# AC7802x register map
Vendor: AutoChips; Series: AC78; File version: 1.0
CPU: CM0PLUS r0p1, little endian, no MPU, no FPU, VTOR, 2 interrupt priority bits
Registers are 32-bit, read-write, reset 0x0 unless marked. A register's access mark holds for its fields unless they carry their own. Offsets are from the block's base; [hi:lo] are bit positions; {n}, {i} and the like mark numbered series; 'fields as' and 'values as' point back to an identical list.

## PWM2 — Pulse Width Modulation
Base 0x40015000
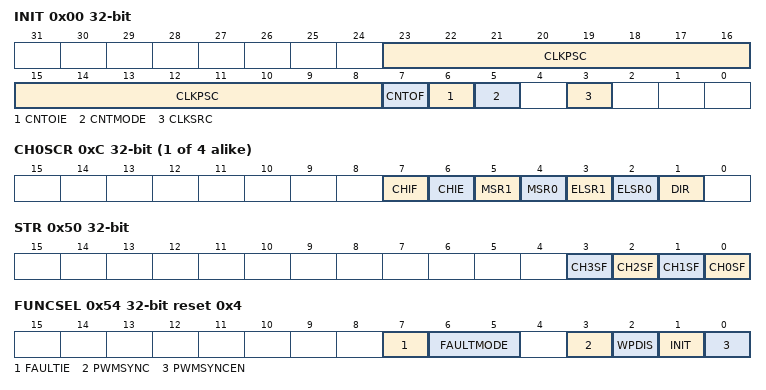
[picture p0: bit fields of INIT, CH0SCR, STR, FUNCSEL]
0x00 INIT — PWM Initialize, Include Clock and Prescale Setting
  [23:8] CLKPSC — Prescale Factor Selection
  [7] CNTOF — PWM Counter Overflow Flag
    0=PWM counter has not overflowed; 1=PWM counter has overflowed
  [6] CNTOIE — PWM Counter Overflow Interrupt Enable
    0=Disable CNTOF interrupts. Use software polling.; 1=Enable CNTOF interrupts. An interrupt is generated when CNTOF equals one.
  [5] CNTMODE — PWM Counter Mode Select
    0=Up Counting mode; 1=Up-Down Counting mode
  [3] CLKSRC — Clock Source Selection
    0=No clock selected. This in effect disables the PWM counter.; 1=APB clock
0x04 CNT — PWM Counter Current Count Value
  [15:0] COUNT — Current Counter Value
0x08 MCVR — PWM Counter Max Count Value Register
  [15:0] MCVR — Counter Max Count Value
{0xC+8i} CH{i}SCR (i=0..3) — Channel (n) Status And Control Register
  [7] CHIF — Channel Interrupt Flag
    0=No channel event has occurred; 1=Channel event has occurred
  [6] CHIE — Channel Interrupt Enable
    0=Disable channel interrupts. Use software polling.; 1=Enable channel interrupts
  [5] MSR1 — Channel Mode Select Register 1
  [4] MSR0 — Channel Mode Select Register 0
  [3] ELSR1 — Edge or Level Select Register 1
  [2] ELSR0 — Edge or Level Select Register 0
  [1] DIR — Match point direction
    0=Down count match; 1=Up count match
{0x10+8i} CH{i}V (i=0..3) — Channel (n) Value
  [15:0] CHCVAL — Channel Count Value
0x4C CNTIN — Counter Initial Value
  [15:0] CNTINIT
0x50 STR — Status Register
  [all] fields
    values as CH0SCR.CHIF
  [n] CH{n}SF (n=0..3) — Channel {n} Status Flag
0x54 FUNCSEL reset 0x4 — PWM Features(Functions) Mode Selection Register
  [7] FAULTIE — Fault Interrupt Enable
    0=Fault control interrupt is disabled; 1=Fault control interrupt is enabled
  [6:5] FAULTMODE — Fault Control Mode
    0=Fault control is disabled for all channels; 1=Fault control is enabled for even channels only (channels 0, 2, 4, and 6), and the selected mode is the manual fault clearing; 2=Fault control is enabled for all channels, and the selected mode is the manual fault clearing; 3=Fault control is enabled for all channels, and the selected mode is the automatic fault clearing
  [3] PWMSYNC — PWM Synchronization Mode
    0=No restrictions. Software and hardware triggers can be used by MOD, CnV, OUTMASK, and PWM counter synchronization.; 1=Software trigger can only be used by MOD and CnV synchronization, and hardware triggers can only be used by OUTMASK and PWM counter synchronization
  [2] WPDIS — Write Protection Enable Register
    0=Write protection is enabled; 1=Write protection is disabled
  [1] INIT — Initialize The Channels Output
  [0] PWMSYNCEN — PWM Synchronization functio Enable
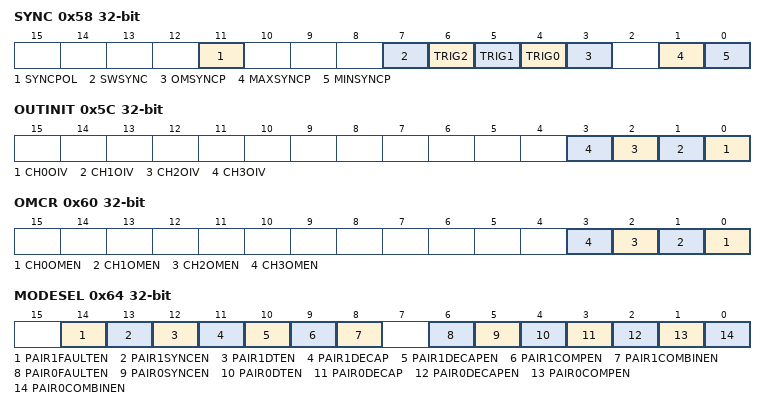
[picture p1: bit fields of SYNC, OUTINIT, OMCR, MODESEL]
0x58 SYNC — Synchronization
  [11] SYNCPOL — CHPOLR Register Synchronization
    0=CHPOLR register is updated with its buffer value at all rising edges of system clock; 1=CHPOLR register is updated with its buffer value by the PWM synchronization
  [7] SWSYNC — PWM Synchronization Software Trigger
    0=Software trigger is not selected; 1=Software trigger is selected
  [6] TRIG2 — PWM Synchronization Hardware Trigger 2
    0=Trigger is disabled; 1=Trigger is enabled
  [5] TRIG1 — PWM Synchronization Hardware Trigger 1
    0=Trigger is disabled; 1=Trigger is enabled
  [4] TRIG0 — PWM Synchronization Hardware Trigger 0
    0=Trigger is disabled; 1=Trigger is enabled
  [3] OMSYNCP — Output Mask Synchronization Point
    0=OUTMASK register is updated with the value of its buffer in all rising edges of the system clock; 1=OUTMASK register is updated with the value of its buffer only by the PWM synchronization
  [1] MAXSYNCP — Maximum Loading Point Enable
    0=The maximum loading point is disabled; 1=The maximum loading point is enabled
  [0] MINSYNCP — Minimum Loading Point Enable
    0=The minimum loading point is disabled; 1=The minimum loading point is enabled
0x5C OUTINIT — Initial Value For Channels Output
  [all] fields
    0=The initialization value is 0; 1=The initialization value is 1
  [n] CH{n}OIV (n=0..3) — Channel {n} Output Initialization Value
0x60 OMCR — Output Mask Control Register
  [all] fields
    0=Channel output is not masked. It continues to operate normally.; 1=Channel output is masked. It is forced to its inactive state.
  [n] CH{n}OMEN (n=0..3) — Channel {n} Output Mask
0x64 MODESEL — PWM Function Mode Selection
  [14] PAIR1FAULTEN — Fault Control Enable For Pair1
    0=The fault control in this pair of channels is disabled; 1=The fault control in this pair of channels is enabled
  [13] PAIR1SYNCEN — Synchronization Enable For Pair1
    0=The PWM synchronization in this pair of channels is disabled; 1=The PWM synchronization in this pair of channels is enabled
  [12] PAIR1DTEN — Deadtime Enable For Pair1
    0=The deadtime insertion in this pair of channels is disabled; 1=The deadtime insertion in this pair of channels is enabled
  [11] PAIR1DECAP — Dual Edge Capture Mode Captures For Pair1
    0=The dual edge captures are inactive; 1=The dual edge captures are active
  [10] PAIR1DECAPEN — Dual Edge Capture Mode Enable For Pair1
    0=The Dual Edge Capture mode in this pair of channels is disabled; 1=The Dual Edge Capture mode in this pair of channels is enabled
  [9] PAIR1COMPEN — Complement Of Channel (n) For Pair1
    0=The channel 3 output is the same as the channel 2 output; 1=The channel 3 output is the complement of the channel 2 output
  [8] PAIR1COMBINEN — Combine Channels For Pair1
    0=Channels 2 and 3 are independent; 1=Channels 2 and 3 are combined
  [6] PAIR0FAULTEN — Fault Control Enable for Pair0
    values as PAIR1FAULTEN
  [5] PAIR0SYNCEN — Synchronization Enable for Pair0
    values as PAIR1SYNCEN
  [4] PAIR0DTEN — Deadtime Enable for Pair0
    values as PAIR1DTEN
  [3] PAIR0DECAP — Dual Edge Capture Mode Captures for Pair0
    values as PAIR1DECAP
  [2] PAIR0DECAPEN — Dual Edge Capture Mode Enable for Pair0
    values as PAIR1DECAPEN
  [1] PAIR0COMPEN — Complement Channels for Pair0
    0=The channel 1 output is the same as the channel 0 output; 1=The channel 1 output is the complement of the channel 0 output
  [0] PAIR0COMBINEN — Combine Channels For Pair0
    0=Channels 0 and 1 are independent; 1=Channels 0 and 1 are combined
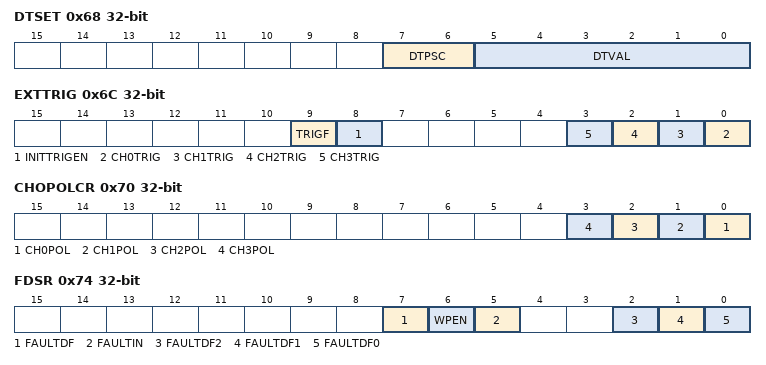
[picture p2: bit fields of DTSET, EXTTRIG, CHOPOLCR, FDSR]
0x68 DTSET — Deadtime Setting Register
  [7:6] DTPSC — Deadtime Prescaler Control Value
    0b0x=Divide the system clock by 1; 2=Divide the system clock by 4; 3=Divide the system clock by 16
  [5:0] DTVAL — Deadtime Value
0x6C EXTTRIG — PWM External Trigger
  [9] TRIGF — Channel Trigger Flag
    0=No channel trigger was generated; 1=A channel trigger was generated
  [8] INITTRIGEN — Initialization Trigger Enable
    0=The generation of initialization trigger is disabled; 1=The generation of initialization trigger is enabled
  [n] CH{n}TRIG (n=0..3) — Channel {n} Trigger Enable
    0=The generation of the channel trigger is disabled; 1=The generation of the channel trigger is enabled
0x70 CHOPOLCR — Channel Output Polarity Register
  [all] fields
    0=The channel polarity is active high; 1=The channel polarity is active low
  [n] CH{n}POL (n=0..3) — Channel {n} Polarity
0x74 FDSR — Fault Detect Status Register
  [7] FAULTDF ro — Fault Detection Flag
    0=No fault condition was detected; 1=A fault condition was detected
  [6] WPEN — Write Protection Enable
    0=Write protection is disabled. Write protected bits can be written.; 1=Write protection is enabled. Write protected bits cannot be written.
  [5] FAULTIN ro — Fault Inputs
    0=The logic OR of the enabled fault inputs is 0; 1=The logic OR of the enabled fault inputs is 1
  [2] FAULTDF2 ro — Fault Detection Flag 2
    0=No fault condition was detected at the fault input; 1=A fault condition was detected at the fault input
  [1] FAULTDF1 ro — Fault Detection Flag 1
    values as FAULTDF2
  [0] FAULTDF0 ro — Fault Detection Flag 0
    values as FAULTDF2
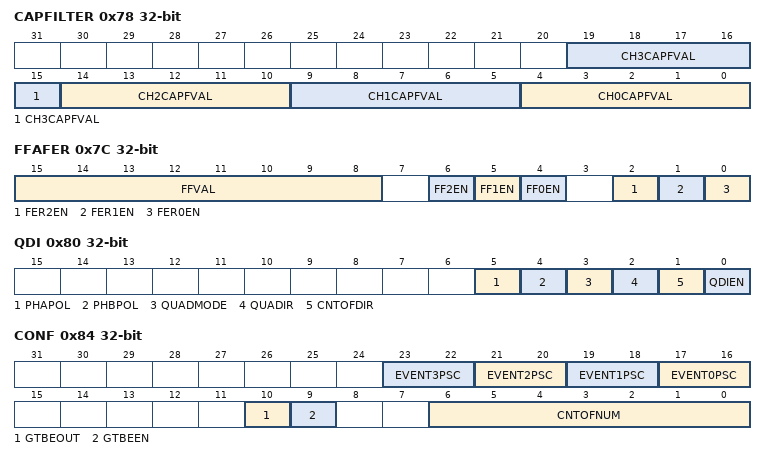
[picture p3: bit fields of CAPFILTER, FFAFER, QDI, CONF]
0x78 CAPFILTER — Input Capture Filter Control
  [5n+4:5n] CH{n}CAPFVAL (n=0..3) — Channel {n} Input Filter
0x7C FFAFER — Fault Filter and Fault Enable Register
  [15:8] FFVAL — Fault Input Filter
  [6] FF2EN — Fault Input 2 Filter Enable
    0=Fault input filter is disabled; 1=Fault input filter is enabled
  [5] FF1EN — Fault Input 1 Filter Enable
    values as FF2EN
  [4] FF0EN — Fault Input 0 Filter Enable
    values as FF2EN
  [2] FER2EN — Fault Input 2 Enable
    0=Fault input is disabled; 1=Fault input is enabled
  [1] FER1EN — Fault Input 1 Enable
    0=Fault input is disabled; 1=Fault input is enabled
  [0] FER0EN — Fault Input 0 Enable
    0=Fault input is disabled; 1=Fault input is enabled
0x80 QDI — Quadrature Decoder Interface Configuration Register
  [5] PHAPOL — Phase A Input Polarity
    0=Normal polarity; 1=Inverted polarity
  [4] PHBPOL — Phase B Input Polarity
    0=Normal polarity; 1=Inverted polarity
  [3] QUADMODE — Quadrature Decoder Mode
    0=Phase A and phase B encoding mode; 1=Count and direction encoding mode
  [2] QUADIR ro — Counting Direction
    0=Counting direction is decreasing; 1=Counting direction is increasing
  [1] CNTOFDIR ro — Overflow Direction
    0=Set on the bottom of counting; 1=Set on the top of counting
  [0] QDIEN — Quadrature Decoder Mode Enable
    0=Quadrature Decoder is Disable; 1=Quadrature Decoder is Enable
0x84 CONF — Configuration
  [2n+17:2n+16] EVENT{n}PSC (n=0..3) — Channel{n} input event prescaler
    0=Event divided by 1; 1=Event divided by 2; 2=Event divided by 4; 3=Event divided by 8
  [10] GTBEOUT — Global Time Base Output
    0=Global time base signal generation is disabled; 1=Global time base signal generation is enabled
  [9] GTBEEN — Global Time Base Enable
    0=Global time base is disabled; 1=Global time base is enabled
  [6:0] CNTOFNUM — Count Overflow Flag Number
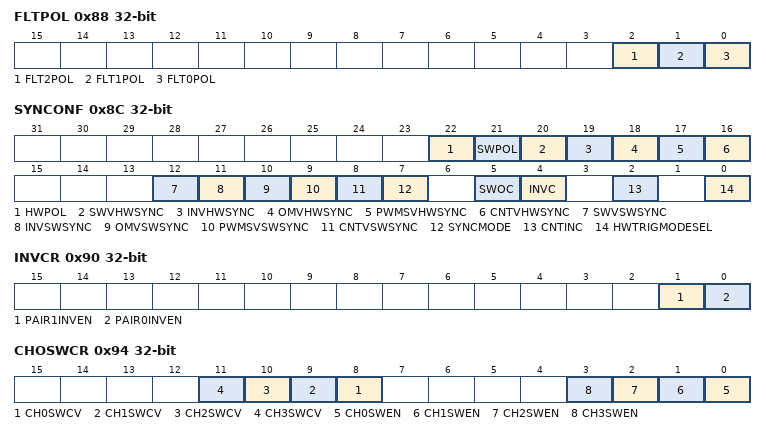
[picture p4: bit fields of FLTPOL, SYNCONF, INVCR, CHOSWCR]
0x88 FLTPOL — PWM Fault Input Polarity
  [all] fields
    0=The fault input polarity is active high; 1=The fault input polarity is active low
  [2] FLT2POL — Fault Input 2 Polarity
  [1] FLT1POL — Fault Input 1 Polarity
  [0] FLT0POL — Fault Input 0 Polarity
0x8C SYNCONF — Synchronization Configuration
  [22] HWPOL — Channel POL synchronization is activeated by a hardware trigger
    0=The hardware trigger does not activate the POL register synchronization; 1=The hardware trigger activates POL register synchronization
  [21] SWPOL — Channel POL synchronization is activeated by a software trigger
    0=The software trigger does not activate the POL register synchronization; 1=The software trigger activates POL register synchronization
  [20] SWVHWSYNC — SWOCTRL register synchronization is activeated by a hardware trigger
    0=A hardware trigger does not activate the SWOCTRL register synchronization; 1=A hardware trigger activates the SWOCTRL register synchronization
  [19] INVHWSYNC — INVCTRL register synchronization is activeated by a hardware trigger
    0=A hardware trigger does not activate the INVCTRL register synchronization; 1=A hardware trigger activates the INVCTRL register synchronization
  [18] OMVHWSYNC — OUTMASK register synchronization is activeated by a hardware trigger
    0=A hardware trigger does not activate the OUTMASK register synchronization; 1=A hardware trigger activates the OUTMASK register synchronization
  [17] PWMSVHWSYNC — MOD, CNTIN, and CV register synchronization is activeated by a hardware trigger
    0=A hardware trigger does not activate MOD, CNTIN, and CV registers synchronization; 1=A hardware trigger activates MOD, CNTIN, and CV registers synchronization
  [16] CNTVHWSYNC — PWM counter synchronization is activeated by a hardware trigger
    0=A hardware trigger does not activate the PWM counter synchronization; 1=A hardware trigger activates the PWM counter synchronization
  [12] SWVSWSYNC — SWOCTRL register synchronization is activeated by a software trigger
    0=The software trigger does not activate the SWOCTRL register synchronization; 1=The software trigger activates the SWOCTRL register synchronization
  [11] INVSWSYNC — INVCTRL register synchronization is activeated by a software trigger
    0=The software trigger does not activate the INVCTRL register synchronization; 1=The software trigger activates the INVCTRL register synchronization
  [10] OMVSWSYNC — OUTMASK register synchronization is activeated by a software trigger
    0=The software trigger does not activate the OUTMASK register synchronization; 1=The software trigger activates the OUTMASK register synchronization
  [9] PWMSVSWSYNC — MOD, CNTIN, and CV register synchronization is activeated by a software trigger
    0=The software trigger does not activate MOD, CNTIN, and CV registers synchronization; 1=The software trigger activates MOD, CNTIN, and CV registers synchronization
  [8] CNTVSWSYNC — PWM counter synchronization is activeated by a software trigger
    0=The software trigger does not activate the PWM counter synchronization; 1=The software trigger activates the PWM counter synchronization
  [7] SYNCMODE — Synchronization Mode
    0=Legacy PWM synchronization is selected; 1=Enhanced PWM synchronization is selected
  [5] SWOC — SWOCTRL Register Synchronization
    0=SWOCTRL register is updated with its buffer value at all rising edges of system clock; 1=SWOCTRL register is updated with its buffer value by the PWM synchronization
  [4] INVC — INVCTRL Register Synchronization
    0=INVCTRL register is updated with its buffer value at all rising edges of system clock; 1=INVCTRL register is updated with its buffer value by the PWM synchronization
  [2] CNTINC — CNTIN Register Synchronization
    0=CNTIN register is updated with its buffer value at all rising edges of system clock; 1=CNTIN register is updated with its buffer value by the PWM synchronization
  [0] HWTRIGMODESEL — Hardware Trigger Mode
    0=PWM clears the TRIGj bit when the hardware trigger j is detected; 1=PWM does not clear the TRIGj bit when the hardware trigger j is detected
0x90 INVCR — PWM Inverse Control Register
  [1] PAIR1INVEN — Pair Channels 1 Inverting Enable
    0=Inverting is disabled; 1=Inverting is enabled
  [0] PAIR0INVEN — Pair Channels 0 Inverting Enable
    0=Inverting is disabled; 1=Inverting is enabled
0x94 CHOSWCR — PWM CHannel Output Software Control Register
  [n+8] CH{n}SWCV (n=0..3) — Channel {n} Software Output Control Value
    0=The software output control forces 0 to the channel output; 1=The software output control forces 1 to the channel output
  [n] CH{n}SWEN (n=0..3) — Channel {n} Software Output Control Enable
    0=The channel output is not affected by software output control; 1=The channel output is affected by software output control
